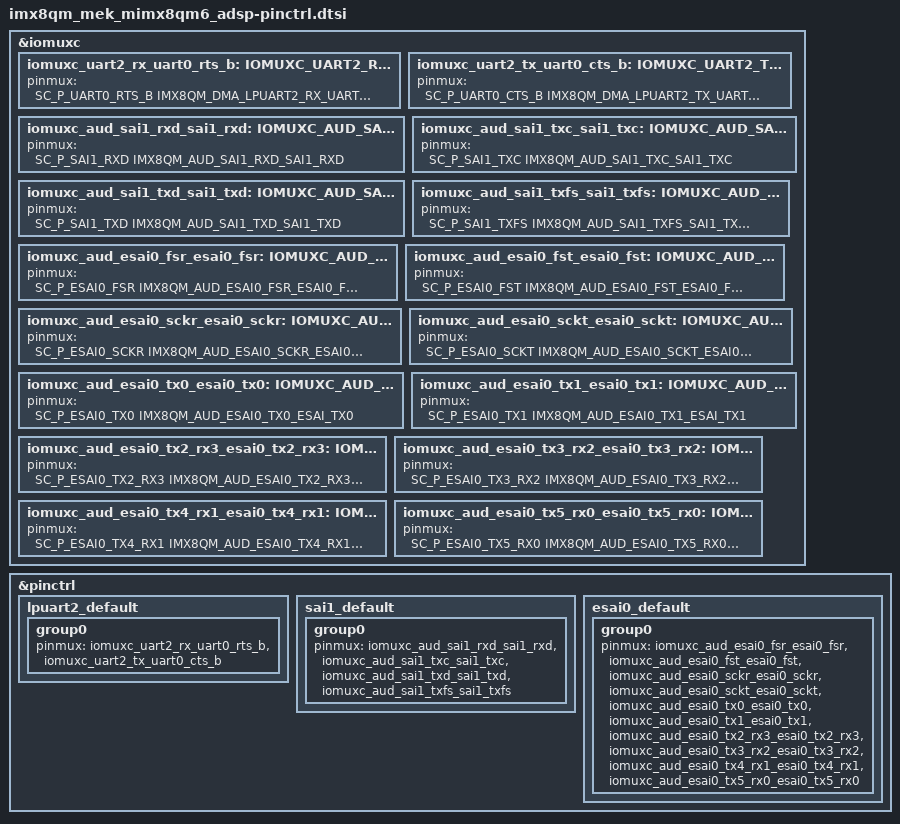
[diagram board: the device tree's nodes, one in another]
/*
 * Copyright 2023, 2025 NXP
 *
 * SPDX-License-Identifier: Apache-2.0
 */

#include <zephyr/dt-bindings/pinctrl/imx8qm-pinctrl.h>

&iomuxc {
	iomuxc_uart2_rx_uart0_rts_b: IOMUXC_UART2_RX_UART0_RTS_B {
		pinmux = <SC_P_UART0_RTS_B IMX8QM_DMA_LPUART2_RX_UART0_RTS_B>;
	};

	iomuxc_uart2_tx_uart0_cts_b: IOMUXC_UART2_TX_UART0_CTS_B {
		pinmux = <SC_P_UART0_CTS_B IMX8QM_DMA_LPUART2_TX_UART0_CTS_B>;
	};

	iomuxc_aud_sai1_rxd_sai1_rxd: IOMUXC_AUD_SAI1_RXD_SAI1_RXD {
		pinmux = <SC_P_SAI1_RXD IMX8QM_AUD_SAI1_RXD_SAI1_RXD>;
	};

	iomuxc_aud_sai1_txc_sai1_txc: IOMUXC_AUD_SAI1_TXC_SAI1_TXC {
		pinmux = <SC_P_SAI1_TXC IMX8QM_AUD_SAI1_TXC_SAI1_TXC>;
	};

	iomuxc_aud_sai1_txd_sai1_txd: IOMUXC_AUD_SAI1_TXD_SAI1_TXD {
		pinmux = <SC_P_SAI1_TXD IMX8QM_AUD_SAI1_TXD_SAI1_TXD>;
	};

	iomuxc_aud_sai1_txfs_sai1_txfs: IOMUXC_AUD_SAI1_TXFS_SAI1_TXFS {
		pinmux = <SC_P_SAI1_TXFS IMX8QM_AUD_SAI1_TXFS_SAI1_TXFS>;
	};

	iomuxc_aud_esai0_fsr_esai0_fsr: IOMUXC_AUD_ESAI0_FSR_ESAI0_FSR {
		pinmux = <SC_P_ESAI0_FSR IMX8QM_AUD_ESAI0_FSR_ESAI0_FSR>;
	};

	iomuxc_aud_esai0_fst_esai0_fst: IOMUXC_AUD_ESAI0_FST_ESAI0_FST {
		pinmux = <SC_P_ESAI0_FST IMX8QM_AUD_ESAI0_FST_ESAI0_FST>;
	};

	iomuxc_aud_esai0_sckr_esai0_sckr: IOMUXC_AUD_ESAI0_SCKR_ESAI0_SCKR {
		pinmux = <SC_P_ESAI0_SCKR IMX8QM_AUD_ESAI0_SCKR_ESAI0_SCKR>;
	};

	iomuxc_aud_esai0_sckt_esai0_sckt: IOMUXC_AUD_ESAI0_SCKT_ESAI0_SCKT {
		pinmux = <SC_P_ESAI0_SCKT IMX8QM_AUD_ESAI0_SCKT_ESAI0_SCKT>;
	};

	iomuxc_aud_esai0_tx0_esai0_tx0: IOMUXC_AUD_ESAI0_TX0_ESAI0_TX0 {
		pinmux = <SC_P_ESAI0_TX0 IMX8QM_AUD_ESAI0_TX0_ESAI_TX0>;
	};

	iomuxc_aud_esai0_tx1_esai0_tx1: IOMUXC_AUD_ESAI0_TX1_ESAI0_TX1 {
		pinmux = <SC_P_ESAI0_TX1 IMX8QM_AUD_ESAI0_TX1_ESAI_TX1>;
	};

	iomuxc_aud_esai0_tx2_rx3_esai0_tx2_rx3: IOMUXC_AUD_ESAI0_TX2_RX3_ESAI0_TX2_RX3 {
		pinmux = <SC_P_ESAI0_TX2_RX3 IMX8QM_AUD_ESAI0_TX2_RX3_ESAI0_TX2_RX3>;
	};

	iomuxc_aud_esai0_tx3_rx2_esai0_tx3_rx2: IOMUXC_AUD_ESAI0_TX3_RX2_ESAI0_TX3_RX2 {
		pinmux = <SC_P_ESAI0_TX3_RX2 IMX8QM_AUD_ESAI0_TX3_RX2_ESAI0_TX3_RX2>;
	};

	iomuxc_aud_esai0_tx4_rx1_esai0_tx4_rx1: IOMUXC_AUD_ESAI0_TX4_RX1_ESAI0_TX4_RX1 {
		pinmux = <SC_P_ESAI0_TX4_RX1 IMX8QM_AUD_ESAI0_TX4_RX1_ESAI0_TX4_RX1>;
	};

	iomuxc_aud_esai0_tx5_rx0_esai0_tx5_rx0: IOMUXC_AUD_ESAI0_TX5_RX0_ESAI0_TX5_RX0 {
		pinmux = <SC_P_ESAI0_TX5_RX0 IMX8QM_AUD_ESAI0_TX5_RX0_ESAI0_TX5_RX0>;
	};
};

&pinctrl {
	lpuart2_default: lpuart2_default {
		group0 {
			pinmux = <&iomuxc_uart2_rx_uart0_rts_b>,
				 <&iomuxc_uart2_tx_uart0_cts_b>;
		};
	};

	sai1_default: sai1_default {
		group0 {
			pinmux = <&iomuxc_aud_sai1_rxd_sai1_rxd>,
				 <&iomuxc_aud_sai1_txc_sai1_txc>,
				 <&iomuxc_aud_sai1_txd_sai1_txd>,
				 <&iomuxc_aud_sai1_txfs_sai1_txfs>;
		};
	};

	esai0_default: esai0_default {
		group0 {
			pinmux = <&iomuxc_aud_esai0_fsr_esai0_fsr>,
				 <&iomuxc_aud_esai0_fst_esai0_fst>,
				 <&iomuxc_aud_esai0_sckr_esai0_sckr>,
				 <&iomuxc_aud_esai0_sckt_esai0_sckt>,
				 <&iomuxc_aud_esai0_tx0_esai0_tx0>,
				 <&iomuxc_aud_esai0_tx1_esai0_tx1>,
				 <&iomuxc_aud_esai0_tx2_rx3_esai0_tx2_rx3>,
				 <&iomuxc_aud_esai0_tx3_rx2_esai0_tx3_rx2>,
				 <&iomuxc_aud_esai0_tx4_rx1_esai0_tx4_rx1>,
				 <&iomuxc_aud_esai0_tx5_rx0_esai0_tx5_rx0>;
		};
	};
};
